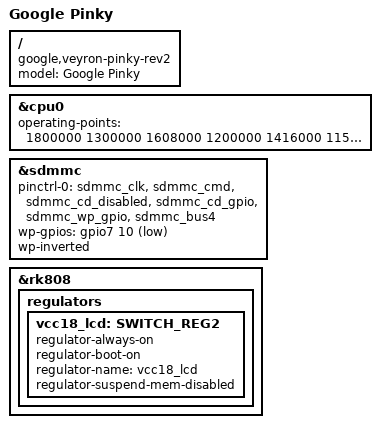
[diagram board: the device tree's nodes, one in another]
/*
 * Google Veyron Pinky Rev 2 board device tree source
 *
 * Copyright 2014 Google, Inc
 *
 * This program is free software; you can redistribute it and/or modify
 * it under the terms of the GNU General Public License version 2 as
 * published by the Free Software Foundation.
 */

/dts-v1/;
#include "rk3288-veyron-chromebook.dtsi"
#include "cros-ec-sbs.dtsi"

/ {
        model = "Google Pinky";
        compatible = "google,veyron-pinky-rev2", "google,veyron-pinky",
                     "google,veyron", "rockchip,rk3288";
};

&cpu0 {
	operating-points = <
		/* KHz    uV */
		1800000 1300000
		1608000 1200000
		1416000 1150000
		1200000 1100000
		1008000 1050000
		 816000 1000000
		 600000  900000
		 408000  850000
		 216000  850000
		 126000  850000
	>;
};

&sdmmc {
	pinctrl-names = "default";
	pinctrl-0 = <&sdmmc_clk &sdmmc_cmd &sdmmc_cd_disabled &sdmmc_cd_gpio
			&sdmmc_wp_gpio &sdmmc_bus4>;
	wp-gpios = <&gpio7 10 GPIO_ACTIVE_LOW>;
	wp-inverted;                             /* AKA active low */
};

&rk808 {
	regulators {
		vcc18_lcd: SWITCH_REG2 {
			regulator-always-on;
			regulator-boot-on;
			regulator-name = "vcc18_lcd";
			regulator-suspend-mem-disabled;
		};
	};
};
